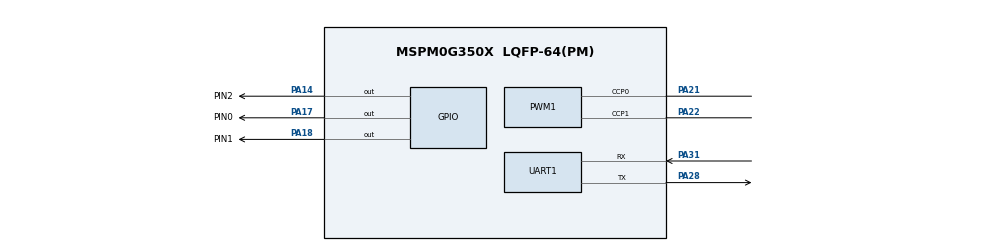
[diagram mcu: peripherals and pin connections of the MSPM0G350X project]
/**
 * @cliArgs --device "MSPM0G350X" --part "Default" --package "LQFP-64(PM)" --product "mspm0_sdk@2.02.00.05"
 * @versions {"tool":"1.21.1+3772"}
 */

/**
 * Import the modules used in this configuration.
 */
const ADC12   = scripting.addModule("/ti/driverlib/ADC12", {}, false);
const ADC121  = ADC12.addInstance();
const GPIO    = scripting.addModule("/ti/driverlib/GPIO", {}, false);
const GPIO1   = GPIO.addInstance();
const GPIO2   = GPIO.addInstance();
const GPIO3   = GPIO.addInstance();
const GPIO4   = GPIO.addInstance();
const GPIO5   = GPIO.addInstance();
const GPIO6   = GPIO.addInstance();
const GPIO7   = GPIO.addInstance();
const GPIO8   = GPIO.addInstance();
const PWM     = scripting.addModule("/ti/driverlib/PWM", {}, false);
const PWM1    = PWM.addInstance();
const SYSCTL  = scripting.addModule("/ti/driverlib/SYSCTL");
const SYSTICK = scripting.addModule("/ti/driverlib/SYSTICK");
const TIMER   = scripting.addModule("/ti/driverlib/TIMER", {}, false);
const TIMER1  = TIMER.addInstance();
const TIMER2  = TIMER.addInstance();
const UART    = scripting.addModule("/ti/driverlib/UART", {}, false);
const UART1   = UART.addInstance();

/**
 * Write custom configuration values to the imported modules.
 */
const gate7  = system.clockTree["MFCLKGATE"];
gate7.enable = true;

ADC121.$name                             = "ADC1";
ADC121.sampClkDiv                        = "DL_ADC12_CLOCK_DIVIDE_8";
ADC121.repeatMode                        = true;
ADC121.powerDownMode                     = "DL_ADC12_POWER_DOWN_MODE_MANUAL";
ADC121.peripheral.adcPin0.$assign        = "PA15";
ADC121.adcPin0Config.hideOutputInversion = scripting.forceWrite(false);
ADC121.adcPin0Config.$name               = "ti_driverlib_gpio_GPIOPinGeneric4";

const Board = scripting.addModule("/ti/driverlib/Board", {}, false);

GPIO1.port                               = "PORTB";
GPIO1.$name                              = "Motor";
GPIO1.associatedPins[0].$name            = "PIN_1";
GPIO1.associatedPins[0].assignedPin      = "3";
GPIO1.associatedPins[0].internalResistor = "PULL_DOWN";

GPIO2.$name                              = "KEYS";
GPIO2.port                               = "PORTB";
GPIO2.associatedPins.create(2);
GPIO2.associatedPins[0].$name            = "PIN_0";
GPIO2.associatedPins[0].assignedPin      = "8";
GPIO2.associatedPins[0].direction        = "INPUT";
GPIO2.associatedPins[0].internalResistor = "PULL_UP";
GPIO2.associatedPins[1].$name            = "KEY_1_PIN";
GPIO2.associatedPins[1].direction        = "INPUT";
GPIO2.associatedPins[1].internalResistor = "PULL_UP";
GPIO2.associatedPins[1].assignedPin      = "9";

GPIO3.port                               = "PORTA";
GPIO3.$name                              = "Beep";
GPIO3.associatedPins[0].$name            = "PIN_2";
GPIO3.associatedPins[0].assignedPin      = "9";
GPIO3.associatedPins[0].internalResistor = "PULL_UP";
GPIO3.associatedPins[0].initialValue     = "SET";

GPIO4.$name                         = "GPIO_GRP_2";
GPIO4.port                          = "PORTB";
GPIO4.associatedPins[0].$name       = "PIN_3";
GPIO4.associatedPins[0].assignedPin = "6";

GPIO5.$name                         = "MOTOR_A";
GPIO5.port                          = "PORTB";
GPIO5.associatedPins.create(2);
GPIO5.associatedPins[0].$name       = "AIN1";
GPIO5.associatedPins[0].assignedPin = "20";
GPIO5.associatedPins[1].$name       = "AIN2";
GPIO5.associatedPins[1].assignedPin = "24";

GPIO6.$name                         = "MOTOR_B";
GPIO6.port                          = "PORTB";
GPIO6.associatedPins.create(2);
GPIO6.associatedPins[0].$name       = "BIN1";
GPIO6.associatedPins[0].assignedPin = "19";
GPIO6.associatedPins[1].$name       = "BIN2";
GPIO6.associatedPins[1].assignedPin = "18";

GPIO7.$name                         = "Gray_Address";
GPIO7.associatedPins.create(3);
GPIO7.associatedPins[0].$name       = "PIN0";
GPIO7.associatedPins[0].pin.$assign = "PA17";
GPIO7.associatedPins[1].$name       = "PIN1";
GPIO7.associatedPins[1].pin.$assign = "PA18";
GPIO7.associatedPins[2].$name       = "PIN2";
GPIO7.associatedPins[2].pin.$assign = "PA14";

GPIO8.$name                               = "ENCODERL";
GPIO8.associatedPins.create(4);
GPIO8.associatedPins[0].$name             = "A1side";
GPIO8.associatedPins[0].direction         = "INPUT";
GPIO8.associatedPins[0].assignedPort      = "PORTA";
GPIO8.associatedPins[0].assignedPin       = "27";
GPIO8.associatedPins[0].interruptEn       = true;
GPIO8.associatedPins[0].interruptPriority = "1";
GPIO8.associatedPins[0].polarity          = "RISE_FALL";
GPIO8.associatedPins[1].$name             = "B1side";
GPIO8.associatedPins[1].direction         = "INPUT";
GPIO8.associatedPins[1].assignedPin       = "26";
GPIO8.associatedPins[1].assignedPort      = "PORTA";
GPIO8.associatedPins[1].interruptEn       = true;
GPIO8.associatedPins[1].interruptPriority = "1";
GPIO8.associatedPins[1].polarity          = "RISE_FALL";
GPIO8.associatedPins[2].$name             = "B2side";
GPIO8.associatedPins[2].direction         = "INPUT";
GPIO8.associatedPins[2].assignedPin       = "25";
GPIO8.associatedPins[2].assignedPort      = "PORTA";
GPIO8.associatedPins[2].interruptEn       = true;
GPIO8.associatedPins[2].interruptPriority = "1";
GPIO8.associatedPins[2].polarity          = "RISE_FALL";
GPIO8.associatedPins[3].$name             = "A2side";
GPIO8.associatedPins[3].direction         = "INPUT";
GPIO8.associatedPins[3].assignedPort      = "PORTA";
GPIO8.associatedPins[3].assignedPin       = "24";
GPIO8.associatedPins[3].interruptEn       = true;
GPIO8.associatedPins[3].interruptPriority = "1";
GPIO8.associatedPins[3].polarity          = "RISE_FALL";

PWM1.$name                              = "PWM";
PWM1.timerCount                         = 3200;
PWM1.timerStartTimer                    = true;
PWM1.peripheral.$assign                 = "TIMG6";
PWM1.peripheral.ccp0Pin.$assign         = "PA21";
PWM1.peripheral.ccp1Pin.$assign         = "PA22";
PWM1.PWM_CHANNEL_0.$name                = "ti_driverlib_pwm_PWMTimerCC0";
PWM1.PWM_CHANNEL_0.invert               = true;
PWM1.PWM_CHANNEL_1.$name                = "ti_driverlib_pwm_PWMTimerCC1";
PWM1.PWM_CHANNEL_1.invert               = true;
PWM1.ccp0PinConfig.direction            = scripting.forceWrite("OUTPUT");
PWM1.ccp0PinConfig.hideOutputInversion  = scripting.forceWrite(false);
PWM1.ccp0PinConfig.onlyInternalResistor = scripting.forceWrite(false);
PWM1.ccp0PinConfig.passedPeripheralType = scripting.forceWrite("Digital");
PWM1.ccp0PinConfig.$name                = "ti_driverlib_gpio_GPIOPinGeneric2";
PWM1.ccp1PinConfig.direction            = scripting.forceWrite("OUTPUT");
PWM1.ccp1PinConfig.hideOutputInversion  = scripting.forceWrite(false);
PWM1.ccp1PinConfig.onlyInternalResistor = scripting.forceWrite(false);
PWM1.ccp1PinConfig.passedPeripheralType = scripting.forceWrite("Digital");
PWM1.ccp1PinConfig.$name                = "ti_driverlib_gpio_GPIOPinGeneric3";

SYSCTL.forceDefaultClkConfig = true;
SYSCTL.clockTreeEn           = true;

SYSTICK.periodEnable      = true;
SYSTICK.systickEnable     = true;
SYSTICK.interruptPriority = "0";
SYSTICK.period            = 32;

TIMER1.$name              = "TIMER_0";
TIMER1.timerClkPrescale   = 100;
TIMER1.timerMode          = "PERIODIC";
TIMER1.timerStartTimer    = true;
TIMER1.interrupts         = ["ZERO"];
TIMER1.timerClkDiv        = 8;
TIMER1.timerPeriod        = "3 ms";
TIMER1.interruptPriority  = "0";
TIMER1.peripheral.$assign = "TIMG0";

TIMER2.$name              = "TIMER_1";
TIMER2.timerClkDiv        = 8;
TIMER2.timerClkPrescale   = 100;
TIMER2.timerMode          = "PERIODIC";
TIMER2.timerPeriod        = "3 ms";
TIMER2.timerStartTimer    = true;
TIMER2.interrupts         = ["ZERO"];
TIMER2.interruptPriority  = "1";
TIMER2.peripheral.$assign = "TIMG8";

UART1.$name                    = "UART_0";
UART1.uartClkSrc               = "MFCLK";
UART1.enabledInterrupts        = ["RX"];
UART1.interruptPriority        = "2";
UART1.peripheral.$assign       = "UART0";
UART1.peripheral.rxPin.$assign = "PA31";
UART1.peripheral.txPin.$assign = "PA28";
UART1.txPinConfig.$name        = "ti_driverlib_gpio_GPIOPinGeneric0";
UART1.rxPinConfig.$name        = "ti_driverlib_gpio_GPIOPinGeneric1";

/**
 * Pinmux solution for unlocked pins/peripherals. This ensures that minor changes to the automatic solver in a future
 * version of the tool will not impact the pinmux you originally saw.  These lines can be completely deleted in order to
 * re-solve from scratch.
 */
ADC121.peripheral.$suggestSolution           = "ADC1";
Board.peripheral.$suggestSolution            = "DEBUGSS";
Board.peripheral.swclkPin.$suggestSolution   = "PA20";
Board.peripheral.swdioPin.$suggestSolution   = "PA19";
GPIO1.associatedPins[0].pin.$suggestSolution = "PB3";
GPIO2.associatedPins[0].pin.$suggestSolution = "PB8";
GPIO2.associatedPins[1].pin.$suggestSolution = "PB9";
GPIO3.associatedPins[0].pin.$suggestSolution = "PA9";
GPIO4.associatedPins[0].pin.$suggestSolution = "PB6";
GPIO5.associatedPins[0].pin.$suggestSolution = "PB20";
GPIO5.associatedPins[1].pin.$suggestSolution = "PB24";
GPIO6.associatedPins[0].pin.$suggestSolution = "PB19";
GPIO6.associatedPins[1].pin.$suggestSolution = "PB18";
GPIO8.associatedPins[0].pin.$suggestSolution = "PA27";
GPIO8.associatedPins[1].pin.$suggestSolution = "PA26";
GPIO8.associatedPins[2].pin.$suggestSolution = "PA25";
GPIO8.associatedPins[3].pin.$suggestSolution = "PA24";
